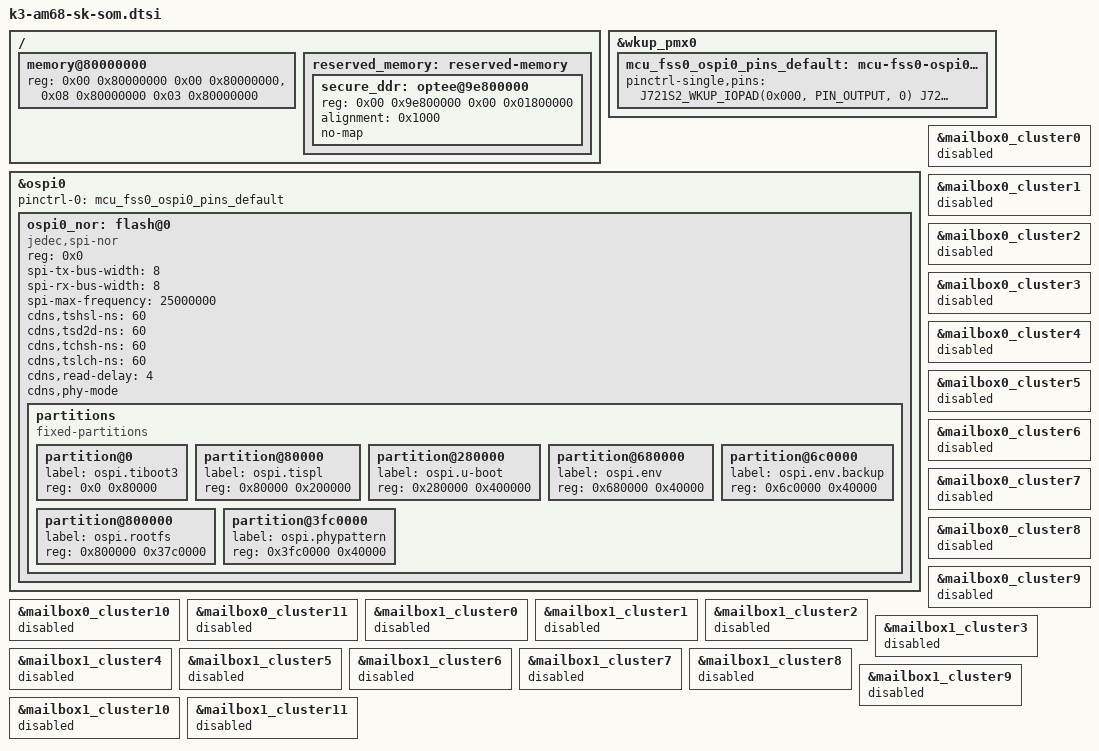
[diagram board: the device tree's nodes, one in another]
// SPDX-License-Identifier: GPL-2.0
/*
 * Copyright (C) 2022 Texas Instruments Incorporated - https://www.ti.com/
 */

/dts-v1/;

#include "k3-j721s2.dtsi"
#include <dt-bindings/gpio/gpio.h>

/ {
	memory@80000000 {
		device_type = "memory";
		/* 16 GB RAM */
		reg = <0x00 0x80000000 0x00 0x80000000>,
		      <0x08 0x80000000 0x03 0x80000000>;
	};

	/* Reserving memory regions still pending */
	reserved_memory: reserved-memory {
		#address-cells = <2>;
		#size-cells = <2>;
		ranges;

		secure_ddr: optee@9e800000 {
			reg = <0x00 0x9e800000 0x00 0x01800000>;
			alignment = <0x1000>;
			no-map;
		};
	};
};

&wkup_pmx0 {
	mcu_fss0_ospi0_pins_default: mcu-fss0-ospi0-pins-default {
		pinctrl-single,pins = <
			J721S2_WKUP_IOPAD(0x000, PIN_OUTPUT, 0) /* (D19) MCU_OSPI0_CLK */
			J721S2_WKUP_IOPAD(0x02c, PIN_OUTPUT, 0) /* (F15) MCU_OSPI0_CSn0 */
			J721S2_WKUP_IOPAD(0x03c, PIN_OUTPUT, 0) /* (F17) MCU_OSPI0_CSn3 */
			J721S2_WKUP_IOPAD(0x00c, PIN_INPUT, 0) /* (C19) MCU_OSPI0_D0 */
			J721S2_WKUP_IOPAD(0x010, PIN_INPUT, 0) /* (F16) MCU_OSPI0_D1 */
			J721S2_WKUP_IOPAD(0x014, PIN_INPUT, 0) /* (G15) MCU_OSPI0_D2 */
			J721S2_WKUP_IOPAD(0x018, PIN_INPUT, 0) /* (F18) MCU_OSPI0_D3 */
			J721S2_WKUP_IOPAD(0x01c, PIN_INPUT, 0) /* (E19) MCU_OSPI0_D4 */
			J721S2_WKUP_IOPAD(0x020, PIN_INPUT, 0) /* (G19) MCU_OSPI0_D5 */
			J721S2_WKUP_IOPAD(0x024, PIN_INPUT, 0) /* (F19) MCU_OSPI0_D6 */
			J721S2_WKUP_IOPAD(0x028, PIN_INPUT, 0) /* (F20) MCU_OSPI0_D7 */
			J721S2_WKUP_IOPAD(0x008, PIN_INPUT, 0) /* (E18) MCU_OSPI0_DQS */
			J721S2_WKUP_IOPAD(0x004, PIN_INPUT, 0) /* (E20) MCU_OSPI0_LBCLKO */
		>;
	};
};

&ospi0 {
	pinctrl-names = "default";
	pinctrl-0 = <&mcu_fss0_ospi0_pins_default>;

	ospi0_nor: flash@0 {
		compatible = "jedec,spi-nor";
		reg = <0x0>;
		spi-tx-bus-width = <8>;
		spi-rx-bus-width = <8>;
		spi-max-frequency = <25000000>;
		cdns,tshsl-ns = <60>;
		cdns,tsd2d-ns = <60>;
		cdns,tchsh-ns = <60>;
		cdns,tslch-ns = <60>;
		cdns,read-delay = <4>;
		cdns,phy-mode;

		partitions {
			compatible = "fixed-partitions";
			#address-cells = <1>;
			#size-cells = <1>;

			partition@0 {
				label = "ospi.tiboot3";
				reg = <0x0 0x80000>;
			};

			partition@80000 {
				label = "ospi.tispl";
				reg = <0x80000 0x200000>;
			};

			partition@280000 {
				label = "ospi.u-boot";
				reg = <0x280000 0x400000>;
			};

			partition@680000 {
				label = "ospi.env";
				reg = <0x680000 0x40000>;
			};

			partition@6c0000 {
				label = "ospi.env.backup";
				reg = <0x6c0000 0x40000>;
			};

			partition@800000 {
				label = "ospi.rootfs";
				reg = <0x800000 0x37c0000>;
			};

			partition@3fc0000 {
				label = "ospi.phypattern";
				reg = <0x3fc0000 0x40000>;
			};
		};
	};
};

&mailbox0_cluster0 {
	status = "disabled";
};

&mailbox0_cluster1 {
	status = "disabled";
};

&mailbox0_cluster2 {
	status = "disabled";
};

&mailbox0_cluster3 {
	status = "disabled";
};

&mailbox0_cluster4 {
	status = "disabled";
};

&mailbox0_cluster5 {
	status = "disabled";
};

&mailbox0_cluster6 {
	status = "disabled";
};

&mailbox0_cluster7 {
	status = "disabled";
};

&mailbox0_cluster8 {
	status = "disabled";
};

&mailbox0_cluster9 {
	status = "disabled";
};

&mailbox0_cluster10 {
	status = "disabled";
};

&mailbox0_cluster11 {
	status = "disabled";
};

&mailbox1_cluster0 {
	status = "disabled";
};

&mailbox1_cluster1 {
	status = "disabled";
};

&mailbox1_cluster2 {
	status = "disabled";
};

&mailbox1_cluster3 {
	status = "disabled";
};

&mailbox1_cluster4 {
	status = "disabled";
};

&mailbox1_cluster5 {
	status = "disabled";
};

&mailbox1_cluster6 {
	status = "disabled";
};

&mailbox1_cluster7 {
	status = "disabled";
};

&mailbox1_cluster8 {
	status = "disabled";
};

&mailbox1_cluster9 {
	status = "disabled";
};

&mailbox1_cluster10 {
	status = "disabled";
};

&mailbox1_cluster11 {
	status = "disabled";
};
